# ALWAYS_ON_CM2 register map
Vendor: Texas Instruments
Peripheral module from a debugger description file (folder omap4460).
Registers are 32-bit, access per field, reset 0x30000 unless marked. A register's access mark holds for its fields unless they carry their own. Offsets are as the file gives them; lines under a group give offsets from that group; [hi:lo] are bit positions; {n}, {i} and the like mark numbered series; 'fields as' and 'values as' point back to an identical list; <NAME> marks a mode.

## ALWAYS_ON_CM2
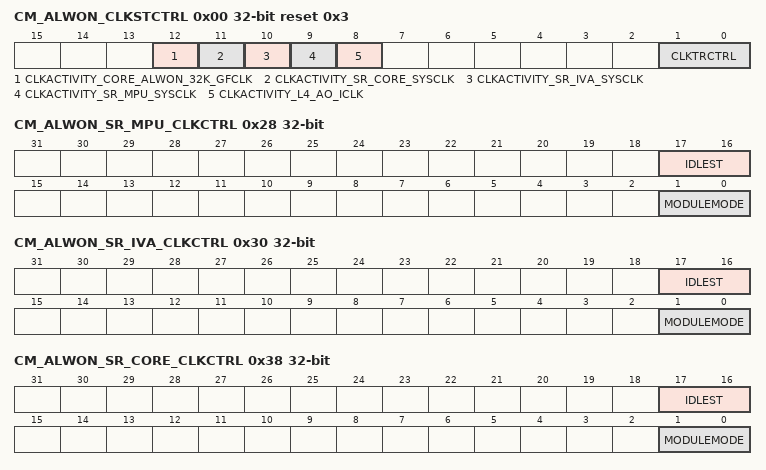
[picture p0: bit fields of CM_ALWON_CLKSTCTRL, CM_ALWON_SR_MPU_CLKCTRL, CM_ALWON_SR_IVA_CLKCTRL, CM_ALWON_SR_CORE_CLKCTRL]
0x00 CM_ALWON_CLKSTCTRL reset 0x3 — This register enables the domain power state transition. It controls the hardware supervised domain power state transition between ON-ACTIVE and ON-INACTIVE states. It also holds 1 status bit per clock input of the domain.
  [12] CLKACTIVITY_CORE_ALWON_32K_GFCLK ro — This field indicates the state of the CORE_ALWON_32K_GFCLK clock in the domain. [warm reset insensitive]
    0=CLKACTIVITY_CORE_ALWON_32K_GFCLK_0_r (Corresponding clock is definitely gated.); 1=CLKACTIVITY_CORE_ALWON_32K_GFCLK_1_r (Corresponding clock is running or gating/ungating transition is ongoing.)
  [11] CLKACTIVITY_SR_CORE_SYSCLK ro — This field indicates the state of the SR_CORE_SYSCLK clock input of the domain. [warm reset insensitive]
    0=CLKACTIVITY_SR_CORE_SYSCLK_0_r (Corresponding clock is definitely gated); 1=CLKACTIVITY_SR_CORE_SYSCLK_1_r (Corresponding clock is running or gating/ungating transition is ongoing)
  [10] CLKACTIVITY_SR_IVA_SYSCLK ro — This field indicates the state of the SR_IVA_SYSCLK clock input of the domain. [warm reset insensitive]
    0=CLKACTIVITY_SR_IVA_SYSCLK_0_r (Corresponding clock is definitely gated); 1=CLKACTIVITY_SR_IVA_SYSCLK_1_r (Corresponding clock is running or gating/ungating transition is ongoing)
  [9] CLKACTIVITY_SR_MPU_SYSCLK ro — This field indicates the state of the SR_MPU_SYSCLK clock input of the domain. [warm reset insensitive]
    0=CLKACTIVITY_SR_MPU_SYSCLK_0_r (Corresponding clock is definitely gated); 1=CLKACTIVITY_SR_MPU_SYSCLK_1_r (Corresponding clock is running or gating/ungating transition is ongoing)
  [8] CLKACTIVITY_L4_AO_ICLK ro — This field indicates the state of the L4_AO_ICLK clock of the domain. [warm reset insensitive]
    0=CLKACTIVITY_L4_AO_ICLK_0_r (Corresponding clock is definitely gated); 1=CLKACTIVITY_L4_AO_ICLK_1_r (Corresponding clock is running or gating/ungating transition is ongoing)
  [1:0] CLKTRCTRL rw — Controls the clock state transition of the ALWONCORE clock domain.
    0=NO_SLEEP: Sleep transition cannot be initiated. Wakeup transition may however occur.; 1=CLKTRCTRL_1_r (Reserved); 2=SW_WKUP: Start a software forced wake-up transition on the domain; 3=HW_AUTO: Automatic transition is enabled. Sleep and wakeup transition are based upon hardware conditions.
0x28 CM_ALWON_SR_MPU_CLKCTRL — This register manages the SR_MPU clocks.
  [17:16] IDLEST ro — Module idle status. [warm reset insensitive]
    0=IDLEST_0_r (Module is fully functional, including INTRCONN); 1=IDLEST_1_r (Module is performing transition: wakeup, or sleep, or sleep abortion); 2=IDLEST_2_r (Module is in idle mode (only INTRCONN part). It is functional if using separate functional clock); 3=IDLEST_3_r (Module is disabled and cannot be accessed)
  [1:0] MODULEMODE rw — Control the way mandatory clocks are managed.
    0=Module is disable by software. Any INTRCONN access to module results in an error, except if resulting from a module wakeup (asynchronous wakeup).; 1=MODULEMODE_1_r (Reserved); 2=Module is explicitly enabled. Interface clock (if not used for functions) may be gated according to the clock domain state. Functional clocks are guarantied to stay present. As long as in this configuration, power domain sleep transition cannot happen.; 3=MODULEMODE_3_r (Reserved)
0x30 CM_ALWON_SR_IVA_CLKCTRL — This register manages the SR_IVA clocks.
  fields as CM_ALWON_SR_MPU_CLKCTRL
0x38 CM_ALWON_SR_CORE_CLKCTRL — This register manages the SR_CORE clocks.
  fields as CM_ALWON_SR_MPU_CLKCTRL
0x40 CM_ALWON_USBPHY_CLKCTRL reset 0x0 — This register manages the USB PHY 32KHz clock.
  [8] OPTFCLKEN_CLK32K rw — Optional functional clock control.
    0=Optional functional clock is disabled; 1=Optional functional clock is enabled
